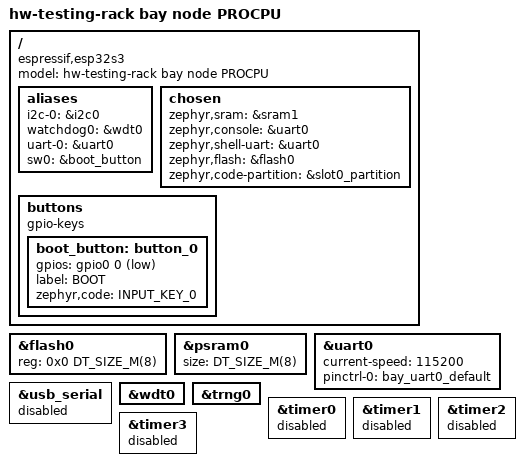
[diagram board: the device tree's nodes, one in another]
/*
 * hw-testing-rack bay node: ESP32-S3-WROOM-1-N8R8 (8 MB flash, 8 MB octal
 * PSRAM on IO35-IO37).  The PSRAM holds the camera's frames and a few large
 * buffers; the pin map is a DevKitC-1 v1.1's (README, Pin map).
 *
 * SPDX-License-Identifier: Apache-2.0
 */
/dts-v1/;

#include <espressif/esp32s3/esp32s3.dtsi>
#include <zephyr/dt-bindings/input/input-event-codes.h>
#include <espressif/partitions_0x0_default_8M.dtsi>
#include "bay_node-pinctrl.dtsi"
#include "bay_node.dtsi"

/ {
	model = "hw-testing-rack bay node PROCPU";
	compatible = "espressif,esp32s3";

	aliases {
		i2c-0 = &i2c0;
		watchdog0 = &wdt0;
		uart-0 = &uart0;
		sw0 = &boot_button;
	};

	chosen {
		zephyr,sram = &sram1;
		zephyr,console = &uart0;
		zephyr,shell-uart = &uart0;
		zephyr,flash = &flash0;
		zephyr,code-partition = &slot0_partition;
	};

	buttons {
		compatible = "gpio-keys";

		/* SW2 on IO0: strapping pin, free to read once the node has booted */
		boot_button: button_0 {
			gpios = <&gpio0 0 (GPIO_PULL_UP | GPIO_ACTIVE_LOW)>;
			label = "BOOT";
			zephyr,code = <INPUT_KEY_0>;
		};
	};
};

&flash0 {
	reg = <0x0 DT_SIZE_M(8)>;
	ranges = <0x0 0x0 DT_SIZE_M(8)>;
};

&psram0 {
	size = <DT_SIZE_M(8)>;
};

/* TXD0/RXD0 test pads: logs and shell during bring-up */
&uart0 {
	status = "okay";
	current-speed = <115200>;
	pinctrl-0 = <&bay_uart0_default>;
	pinctrl-names = "default";
};

/*
 * The USB-Serial-JTAG shares the internal PHY with the OTG controller; the
 * application hands the PHY back to it in SERVICE mode (flash/JTAG through
 * the front port), no Zephyr driver needed.
 */
&usb_serial {
	status = "disabled";
};

&wdt0 {
	status = "okay";
};

&trng0 {
	status = "okay";
};

&timer0 {
	status = "disabled";
};

&timer1 {
	status = "disabled";
};

&timer2 {
	status = "disabled";
};

&timer3 {
	status = "disabled";
};
